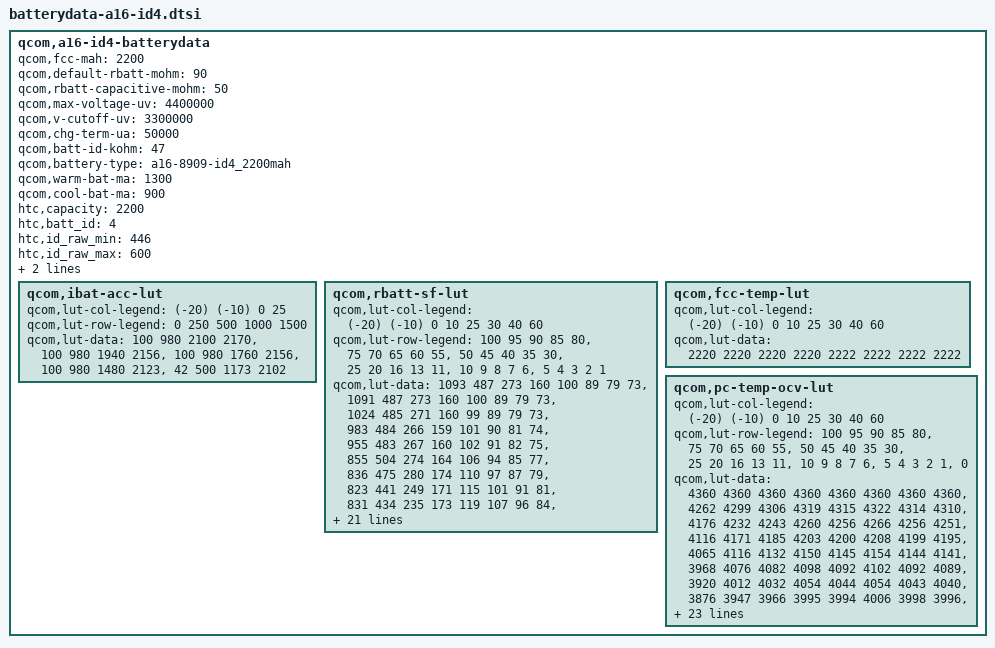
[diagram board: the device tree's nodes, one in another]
/* Copyright (c) 2013, The Linux Foundation. All rights reserved.
 *
 * This program is free software; you can redistribute it and/or modify
 * it under the terms of the GNU General Public License version 2 and
 * only version 2 as published by the Free Software Foundation.
 *
 * This program is distributed in the hope that it will be useful,
 * but WITHOUT ANY WARRANTY; without even the implied warranty of
 * MERCHANTABILITY or FITNESS FOR A PARTICULAR PURPOSE.  See the
 * GNU General Public License for more details.
 */

qcom,a16-id4-batterydata {
	qcom,fcc-mah = <2200>;
	qcom,default-rbatt-mohm = <90>;
	qcom,rbatt-capacitive-mohm = <50>;
	qcom,max-voltage-uv = <4400000>;
	qcom,v-cutoff-uv = <3300000>;
	qcom,chg-term-ua = <50000>;
	qcom,batt-id-kohm = <47>;
	qcom,battery-type = "a16-8909-id4_2200mah";
	qcom,warm-bat-ma = <1300>;
	qcom,cool-bat-ma = <900>;
	htc,capacity = <2200>;
	htc,batt_id = <4>;
	htc,id_raw_min = <446>;
	htc,id_raw_max = <600>;
	htc,type = <1>;
	htc,model_name = "B0PKX100";

	qcom,ibat-acc-lut {
		qcom,lut-col-legend = <(-20) (-10) 0 25>;
		qcom,lut-row-legend = <0 250 500 1000 1500>;
		qcom,lut-data = <100 980 2100 2170>,
				<100 980 1940 2156>,
				<100 980 1760 2156>,
				<100 980 1480 2123>,
				<42 500 1173 2102>;
	};

	qcom,rbatt-sf-lut {
		qcom,lut-col-legend = <(-20) (-10) 0 10 25 30 40 60>;
		qcom,lut-row-legend = <100 95 90 85 80>,
					<75 70 65 60 55>,
					<50 45 40 35 30>,
					<25 20 16 13 11>,
					<10 9 8 7 6>,
					<5 4 3 2 1>;
		qcom,lut-data = <1093 487 273 160 100 89 79 73>,
				<1091 487 273 160 100 89 79 73>,
				<1024 485 271 160 99 89 79 73>,
				<983 484 266 159 101 90 81 74>,
				<955 483 267 160 102 91 82 75>,
				<855 504 274 164 106 94 85 77>,
				<836 475 280 174 110 97 87 79>,
				<823 441 249 171 115 101 91 81>,
				<831 434 235 173 119 107 96 84>,
				<854 427 226 151 108 99 92 83>,
				<896 431 223 141 95 88 80 74>,
				<935 450 226 141 95 87 79 74>,
				<977 474 233 145 96 90 82 77>,
				<1026 503 248 148 99 93 86 79>,
				<1095 539 271 153 102 94 86 80>,
				<1156 577 301 160 102 92 82 75>,
				<1226 611 326 168 100 89 81 74>,
				<1281 642 335 170 101 89 81 74>,
				<1259 670 338 173 97 87 78 72>,
				<1224 662 351 174 98 89 79 74>,
				<1254 667 363 177 101 90 81 75>,
				<1288 682 377 182 105 92 83 77>,
				<1364 701 394 191 107 94 85 79>,
				<1500 719 413 199 113 98 88 82>,
				<1661 738 427 206 115 99 89 81>,
				<1875 750 434 207 111 95 86 78>,
				<2173 767 447 206 112 95 85 78>,
				<2633 794 475 213 115 98 87 80>,
				<3538 839 517 229 126 107 97 92>,
				<7075 1307 678 530 165 139 134 112>;
	};

	qcom,fcc-temp-lut {
		qcom,lut-col-legend = <(-20) (-10) 0 10 25 30 40 60>;
		qcom,lut-data = <2220 2220 2220 2220 2222 2222 2222 2222>;

	};

	qcom,pc-temp-ocv-lut {
		qcom,lut-col-legend = <(-20) (-10) 0 10 25 30 40 60>;
		qcom,lut-row-legend = <100 95 90 85 80>,
					<75 70 65 60 55>,
					<50 45 40 35 30>,
					<25 20 16 13 11>,
					<10 9 8 7 6>,
					<5 4 3 2 1>,
					<0>;
		qcom,lut-data = <4360 4360 4360 4360 4360 4360 4360 4360>,
				<4262 4299 4306 4319 4315 4322 4314 4310>,
				<4176 4232 4243 4260 4256 4266 4256 4251>,
				<4116 4171 4185 4203 4200 4208 4199 4195>,
				<4065 4116 4132 4150 4145 4154 4144 4141>,
				<3968 4076 4082 4098 4092 4102 4092 4089>,
				<3920 4012 4032 4054 4044 4054 4043 4040>,
				<3876 3947 3966 3995 3994 4006 3998 3996>,
				<3848 3900 3920 3954 3954 3964 3956 3954>,
				<3828 3860 3879 3902 3904 3914 3909 3908>,
				<3810 3832 3845 3862 3862 3870 3864 3864>,
				<3792 3814 3819 3833 3833 3840 3836 3836>,
				<3776 3800 3799 3812 3811 3818 3814 3814>,
				<3758 3788 3786 3792 3793 3798 3796 3794>,
				<3743 3774 3776 3779 3778 3782 3778 3774>,
				<3728 3756 3764 3768 3764 3763 3758 3748>,
				<3716 3732 3742 3748 3744 3739 3735 3722>,
				<3706 3712 3715 3719 3716 3712 3709 3696>,
				<3695 3700 3698 3698 3692 3690 3684 3674>,
				<3684 3692 3692 3692 3688 3685 3680 3670>,
				<3676 3688 3688 3689 3686 3684 3680 3668>,
				<3668 3682 3686 3687 3685 3683 3678 3668>,
				<3658 3676 3682 3685 3684 3682 3678 3666>,
				<3644 3668 3678 3682 3680 3678 3674 3662>,
				<3624 3654 3666 3673 3672 3670 3666 3652>,
				<3594 3627 3637 3650 3646 3643 3640 3620>,
				<3551 3584 3586 3604 3600 3596 3592 3572>,
				<3486 3522 3517 3541 3534 3530 3528 3508>,
				<3392 3434 3417 3454 3446 3444 3442 3424>,
				<3256 3296 3267 3312 3314 3322 3314 3298>,
				<3000 3000 3000 3000 3000 3000 3000 3000>;
	};
};
